# MK64F12 register map
Vendor: Freescale Semiconductor, Inc.; Series: Kinetis_K; File version: 1.6
CPU: CM4 r0p1, little endian, no MPU, FPU, VTOR, 4 interrupt priority bits
Registers are 32-bit, read-write, reset 0x0 unless marked. A register's access mark holds for its fields unless they carry their own. Offsets are from the block's base; [hi:lo] are bit positions; {n}, {i} and the like mark numbered series.

## AXBS — Crossbar switch
Base 0x40004000; register names take the prefix AXBS_
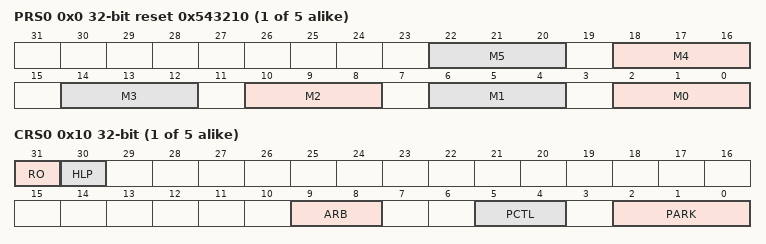
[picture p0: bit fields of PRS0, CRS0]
{0x0+0x100*i} PRS{i} (i=0..4) reset 0x543210 — Priority Registers Slave
  [all] fields
    0=This master has level 1, or highest, priority when accessing the slave port; {v}=This master has level {v+1} priority when accessing the slave port (v=1..6); 7=This master has level 8, or lowest, priority when accessing the slave port
  [4n+2:4n] M{n} (n=0..5) — Master {n} Priority. Sets the arbitration priority for this port on the associated slave port.
{0x10+0x100*i} CRS{i} (i=0..4) — Control Register
  [31] RO — Read Only
    0=The slave port's registers are writeable; 1=The slave port's registers are read-only and cannot be written. Attempted writes have no effect on the registers and result in a bus error response.
  [30] HLP — Halt Low Priority
    0=The low power mode request has the highest priority for arbitration on this slave port; 1=The low power mode request has the lowest initial priority for arbitration on this slave port
  [9:8] ARB — Arbitration Mode
    0=Fixed priority; 1=Round-robin, or rotating, priority
  [5:4] PCTL — Parking Control
    0=When no master makes a request, the arbiter parks the slave port on the master port defined by the PARK field; 1=When no master makes a request, the arbiter parks the slave port on the last master to be in control of the slave port; 2=When no master makes a request, the slave port is not parked on a master and the arbiter drives all outputs to a constant safe state
  [2:0] PARK
    {v}=Park on master port M{v} (v=0..7)
{0x800+0x100*i} MGPCR{i} (i=0..5) — Master General Purpose Control Register
  [2:0] AULB — Arbitrates On Undefined Length Bursts
    0=No arbitration is allowed during an undefined length burst; 1=Arbitration is allowed at any time during an undefined length burst; 2=Arbitration is allowed after four beats of an undefined length burst; 3=Arbitration is allowed after eight beats of an undefined length burst; 4=Arbitration is allowed after 16 beats of an undefined length burst

## DMAMUX — DMA channel multiplexor
Base 0x40021000; register names take the prefix DMAMUX_
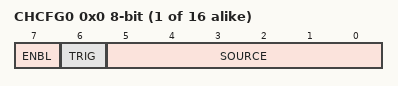
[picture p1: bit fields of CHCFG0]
{0x0+i} CHCFG{i} (i=0..15) 8-bit — Channel Configuration register
  [7] ENBL — DMA Channel Enable
    0=DMA channel is disabled. This mode is primarily used during configuration of the DMAMux. The DMA has separate channel enables/disables, which should be used to disable or reconfigure a DMA channel.; 1=DMA channel is enabled
  [6] TRIG — DMA Channel Trigger Enable
    0=Triggering is disabled. If triggering is disabled and ENBL is set, the DMA Channel will simply route the specified source to the DMA channel. (Normal mode); 1=Triggering is enabled. If triggering is enabled and ENBL is set, the DMAMUX is in Periodic Trigger mode.
  [5:0] SOURCE — DMA Channel Source (Slot)
    0=Disable_Signal; 2=UART0_Rx_Signal; 3=UART0_Tx_Signal; 4=UART1_Rx_Signal; 5=UART1_Tx_Signal; 6=UART2_Rx_Signal; 7=UART2_Tx_Signal; 8=UART3_Rx_Signal; 9=UART3_Tx_Signal; 10=UART4_Signal; 11=UART5_Signal; 12=I2S0_Rx_Signal; 13=I2S0_Tx_Signal; 14=SPI0_Rx_Signal; 15=SPI0_Tx_Signal; 16=SPI1_Signal; 17=SPI2_Signal; 18=I2C0_Signal; 19=I2C1_I2C2_Signal; {v}=FTM0_Channel{v-20}_Signal (v=20..27); 28=FTM1_Channel0_Signal; 29=FTM1_Channel1_Signal; 30=FTM2_Channel0_Signal; 31=FTM2_Channel1_Signal; {v}=FTM3_Channel{v-32}_Signal (v=32..39); 40=ADC0_Signal; 41=ADC1_Signal; 42=CMP0_Signal; 43=CMP1_Signal; 44=CMP2_Signal; 45=DAC0_Signal; 46=DAC1_Signal; 47=CMT_Signal; 48=PDB_Signal; 49=PortA_Signal; 50=PortB_Signal; 51=PortC_Signal; 52=PortD_Signal; 53=PortE_Signal; {v}=IEEE1588Timer{v-54}_Signal (v=54..57); {v}=AlwaysOn{v}_Signal (v=58..63)

## Notices in the file
Redistribution and use in source and binary forms, with or without modification,
are permitted provided that the following conditions are met:
o Redistributions of source code must retain the above copyright notice, this list
of conditions and the following disclaimer.
o Redistributions in binary form must reproduce the above copyright notice, this
list of conditions and the following disclaimer in the documentation and/or
other materials provided with the distribution.
o Neither the name of Freescale Semiconductor, Inc. nor the names of its
contributors may be used to endorse or promote products derived from this
software without specific prior written permission.
THIS SOFTWARE IS PROVIDED BY THE COPYRIGHT HOLDERS AND CONTRIBUTORS "AS IS" AND
ANY EXPRESS OR IMPLIED WARRANTIES, INCLUDING, BUT NOT LIMITED TO, THE IMPLIED
WARRANTIES OF MERCHANTABILITY AND FITNESS FOR A PARTICULAR PURPOSE ARE
DISCLAIMED. IN NO EVENT SHALL THE COPYRIGHT HOLDER OR CONTRIBUTORS BE LIABLE FOR
ANY DIRECT, INDIRECT, INCIDENTAL, SPECIAL, EXEMPLARY, OR CONSEQUENTIAL DAMAGES
(INCLUDING, BUT NOT LIMITED TO, PROCUREMENT OF SUBSTITUTE GOODS OR SERVICES;
LOSS OF USE, DATA, OR PROFITS; OR BUSINESS INTERRUPTION) HOWEVER CAUSED AND ON
ANY THEORY OF LIABILITY, WHETHER IN CONTRACT, STRICT LIABILITY, OR TORT
(INCLUDING NEGLIGENCE OR OTHERWISE) ARISING IN ANY WAY OUT OF THE USE OF THIS
SOFTWARE, EVEN IF ADVISED OF THE POSSIBILITY OF SUCH DAMAGE.
